# ESP32-S2 register map
Vendor: ESPRESSIF SYSTEMS (SHANGHAI) CO., LTD.; Series: ESP32 S-Series; File version: 20
CPU: Xtensa LX7 r0p0, little endian, no MPU, no FPU, 0 interrupt priority bits
Address unit: 32 bits
Registers are 32-bit, read-write, reset 0x0 unless marked. A register's access mark holds for its fields unless they carry their own. Offsets are from the block's base; [hi:lo] are bit positions; {n}, {i} and the like mark numbered series.

## SPI0 — SPI (Serial Peripheral Interface) Controller 0 (MEMSPI)
Base 0x3F403000
Same registers: SPI1 0x3F402000
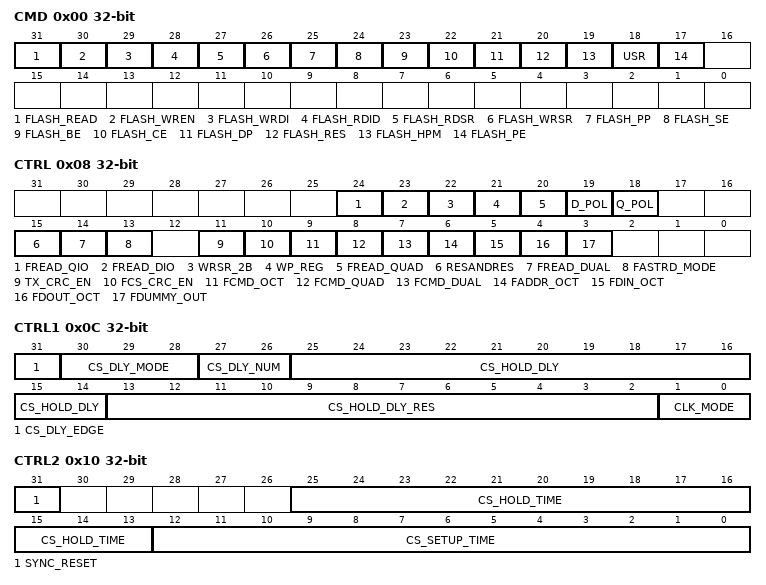
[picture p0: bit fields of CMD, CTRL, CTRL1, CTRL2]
0x00 CMD — SPI Memory Command Register
  [31] FLASH_READ, [30] FLASH_WREN, [29] FLASH_WRDI, [28] FLASH_RDID, [27] FLASH_RDSR, [26] FLASH_WRSR, [25] FLASH_PP, [24] FLASH_SE, [23] FLASH_BE, [22] FLASH_CE, [21] FLASH_DP, [20] FLASH_RES, [19] FLASH_HPM, [18] USR, [17] FLASH_PE
0x04 ADDR — SPI Memory Address Register
  [31:0] USR_ADDR_VALUE
0x08 CTRL — SPI Memory Control Register
  [24] FREAD_QIO, [23] FREAD_DIO, [22] WRSR_2B, [21] WP_REG, [20] FREAD_QUAD, [19] D_POL, [18] Q_POL, [15] RESANDRES, [14] FREAD_DUAL, [13] FASTRD_MODE, [11] TX_CRC_EN, [10] FCS_CRC_EN, [9] FCMD_OCT, [8] FCMD_QUAD, [7] FCMD_DUAL, [6] FADDR_OCT, [5] FDIN_OCT, [4] FDOUT_OCT, [3] FDUMMY_OUT
0x0C CTRL1 — SPI Memory Control1 Register
  [31] CS_DLY_EDGE, [30:28] CS_DLY_MODE, [27:26] CS_DLY_NUM, [25:14] CS_HOLD_DLY, [13:2] CS_HOLD_DLY_RES, [1:0] CLK_MODE
0x10 CTRL2 — SPI Memory Control2 Register
  [31] SYNC_RESET, [25:13] CS_HOLD_TIME, [12:0] CS_SETUP_TIME
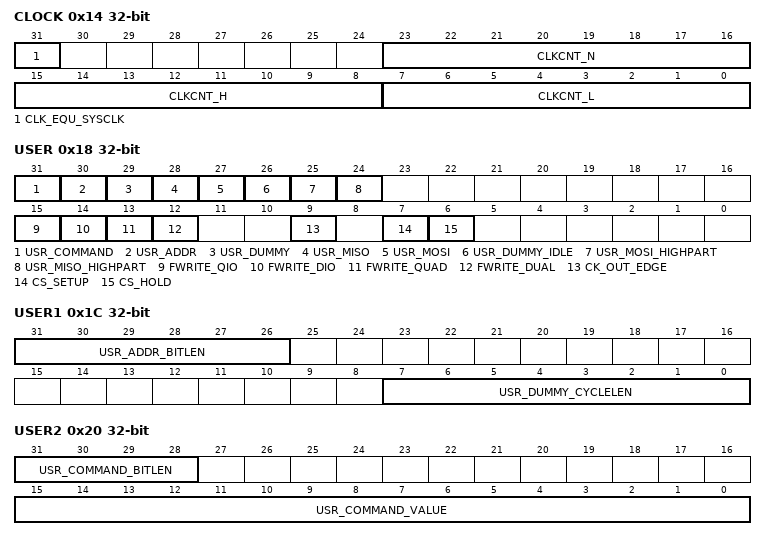
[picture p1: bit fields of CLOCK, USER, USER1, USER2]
0x14 CLOCK — SPI Memory Clock Register
  [31] CLK_EQU_SYSCLK, [23:16] CLKCNT_N, [15:8] CLKCNT_H, [7:0] CLKCNT_L
0x18 USER — SPI Memory User Register
  [31] USR_COMMAND, [30] USR_ADDR, [29] USR_DUMMY, [28] USR_MISO, [27] USR_MOSI, [26] USR_DUMMY_IDLE, [25] USR_MOSI_HIGHPART, [24] USR_MISO_HIGHPART, [15] FWRITE_QIO, [14] FWRITE_DIO, [13] FWRITE_QUAD, [12] FWRITE_DUAL, [9] CK_OUT_EDGE, [7] CS_SETUP, [6] CS_HOLD
0x1C USER1 — SPI Memory User1 Register
  [31:26] USR_ADDR_BITLEN, [7:0] USR_DUMMY_CYCLELEN
0x20 USER2 — SPI Memory User2 Register
  [31:28] USR_COMMAND_BITLEN, [15:0] USR_COMMAND_VALUE
0x24 MOSI_DLEN — SPI Memory MOSI Data Length Register
  [10:0] USR_MOSI_DBITLEN
0x28 MISO_DLEN — SPI Memory MISO Data Length Register
  [10:0] USR_MISO_DBITLEN
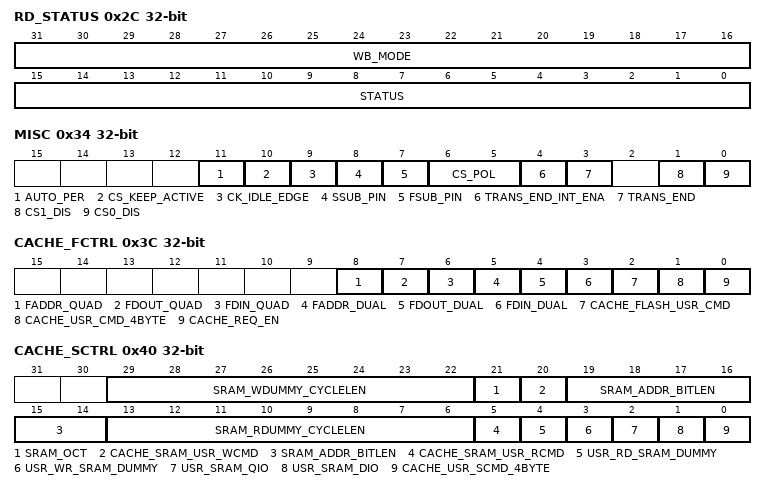
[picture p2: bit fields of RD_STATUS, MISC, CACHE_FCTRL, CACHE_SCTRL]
0x2C RD_STATUS — SPI Memory Read Status Register
  [31:16] WB_MODE, [15:0] STATUS
0x30 EXT_ADDR — SPI Memory External Address Register
0x34 MISC — SPI Memory Miscellaneous Register
  [11] AUTO_PER, [10] CS_KEEP_ACTIVE, [9] CK_IDLE_EDGE, [8] SSUB_PIN, [7] FSUB_PIN, [6:5] CS_POL, [4] TRANS_END_INT_ENA, [3] TRANS_END, [1] CS1_DIS, [0] CS0_DIS
0x38 TX_CRC — SPI Memory Transmit CRC Register
  [31:0] TX_CRC_DATA
0x3C CACHE_FCTRL — SPI Memory Cache Flash Control Register
  [8] FADDR_QUAD, [7] FDOUT_QUAD, [6] FDIN_QUAD, [5] FADDR_DUAL, [4] FDOUT_DUAL, [3] FDIN_DUAL, [2] CACHE_FLASH_USR_CMD, [1] CACHE_USR_CMD_4BYTE, [0] CACHE_REQ_EN
0x40 CACHE_SCTRL — SPI Memory Cache SCTRL Register
  [29:22] SRAM_WDUMMY_CYCLELEN, [21] SRAM_OCT, [20] CACHE_SRAM_USR_WCMD, [19:14] SRAM_ADDR_BITLEN, [13:6] SRAM_RDUMMY_CYCLELEN, [5] CACHE_SRAM_USR_RCMD, [4] USR_RD_SRAM_DUMMY, [3] USR_WR_SRAM_DUMMY, [2] USR_SRAM_QIO, [1] USR_SRAM_DIO, [0] CACHE_USR_SCMD_4BYTE
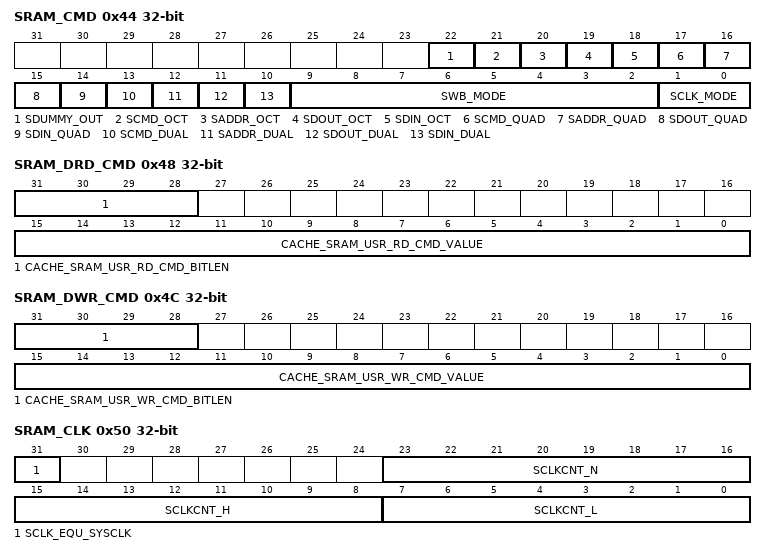
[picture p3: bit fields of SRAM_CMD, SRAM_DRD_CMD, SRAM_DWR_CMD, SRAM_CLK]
0x44 SRAM_CMD — SPI Memory SRAM Command Register
  [22] SDUMMY_OUT, [21] SCMD_OCT, [20] SADDR_OCT, [19] SDOUT_OCT, [18] SDIN_OCT, [17] SCMD_QUAD, [16] SADDR_QUAD, [15] SDOUT_QUAD, [14] SDIN_QUAD, [13] SCMD_DUAL, [12] SADDR_DUAL, [11] SDOUT_DUAL, [10] SDIN_DUAL, [9:2] SWB_MODE, [1:0] SCLK_MODE
0x48 SRAM_DRD_CMD — SPI Memory SRAM Read Command Register
  [31:28] CACHE_SRAM_USR_RD_CMD_BITLEN, [15:0] CACHE_SRAM_USR_RD_CMD_VALUE
0x4C SRAM_DWR_CMD — SPI Memory SRAM Write Command Register
  [31:28] CACHE_SRAM_USR_WR_CMD_BITLEN, [15:0] CACHE_SRAM_USR_WR_CMD_VALUE
0x50 SRAM_CLK — SPI Memory SRAM Clock Register
  [31] SCLK_EQU_SYSCLK, [23:16] SCLKCNT_N, [15:8] SCLKCNT_H, [7:0] SCLKCNT_L
0x54 FSM ro — SPI Memory FSM Register
  [2:0] ST
{0x58+4i} W{i} (i=0..15)
  [31:0] BUF
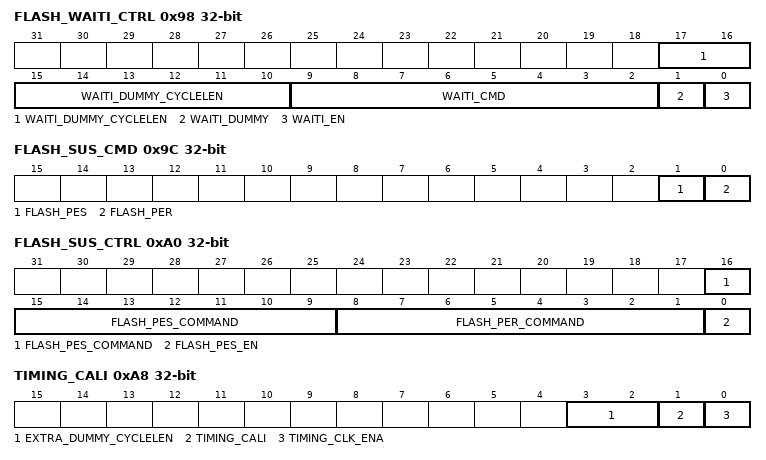
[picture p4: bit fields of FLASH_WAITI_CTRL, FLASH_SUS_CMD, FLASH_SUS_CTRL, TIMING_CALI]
0x98 FLASH_WAITI_CTRL — SPI Memory Flash Wait Idle Control Register
  [17:10] WAITI_DUMMY_CYCLELEN, [9:2] WAITI_CMD, [1] WAITI_DUMMY, [0] WAITI_EN
0x9C FLASH_SUS_CMD — SPI Memory Flash Suspend Command Register
  [1] FLASH_PES, [0] FLASH_PER
0xA0 FLASH_SUS_CTRL — SPI Memory Flash Suspend Control Register
  [16:9] FLASH_PES_COMMAND, [8:1] FLASH_PER_COMMAND, [0] FLASH_PES_EN
0xA4 SUS_STATUS ro — SPI Memory Suspend Status Register
  [0] FLASH_SUS
0xA8 TIMING_CALI — SPI Memory Timing Calibration Register
  [3:2] EXTRA_DUMMY_CYCLELEN, [1] TIMING_CALI, [0] TIMING_CLK_ENA
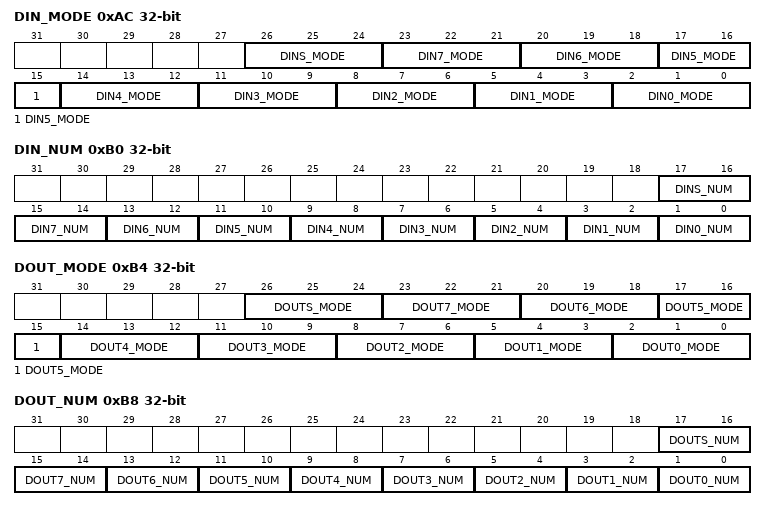
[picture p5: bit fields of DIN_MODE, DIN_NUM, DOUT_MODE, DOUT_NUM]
0xAC DIN_MODE — SPI Memory Data In Mode Register
  [26:24] DINS_MODE, [3n+2:3n] DIN{n}_MODE (n=0..7)
0xB0 DIN_NUM — SPI Memory Data In Number Register
  [17:16] DINS_NUM, [2n+1:2n] DIN{n}_NUM (n=0..7)
0xB4 DOUT_MODE — SPI Memory Data Out Mode Register
  [26:24] DOUTS_MODE, [3n+2:3n] DOUT{n}_MODE (n=0..7)
0xB8 DOUT_NUM — SPI Memory Data Out Number Register
  [17:16] DOUTS_NUM, [2n+1:2n] DOUT{n}_NUM (n=0..7)
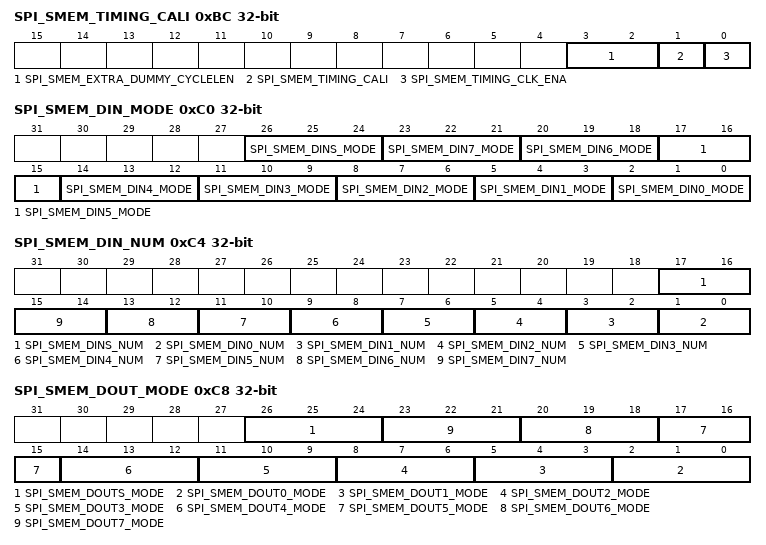
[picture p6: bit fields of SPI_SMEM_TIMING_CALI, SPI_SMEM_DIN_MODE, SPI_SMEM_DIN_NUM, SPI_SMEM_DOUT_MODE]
0xBC SPI_SMEM_TIMING_CALI — SPI Memory SRAM Timing Calibration Register
  [3:2] SPI_SMEM_EXTRA_DUMMY_CYCLELEN, [1] SPI_SMEM_TIMING_CALI, [0] SPI_SMEM_TIMING_CLK_ENA
0xC0 SPI_SMEM_DIN_MODE — SPI Memory SRAM Data In Mode Register
  [26:24] SPI_SMEM_DINS_MODE, [3n+2:3n] SPI_SMEM_DIN{n}_MODE (n=0..7)
0xC4 SPI_SMEM_DIN_NUM — SPI Memory SRAM Data In Number Register
  [17:16] SPI_SMEM_DINS_NUM, [2n+1:2n] SPI_SMEM_DIN{n}_NUM (n=0..7)
0xC8 SPI_SMEM_DOUT_MODE — SPI Memory SRAM Data Out Mode Register
  [26:24] SPI_SMEM_DOUTS_MODE, [3n+2:3n] SPI_SMEM_DOUT{n}_MODE (n=0..7)
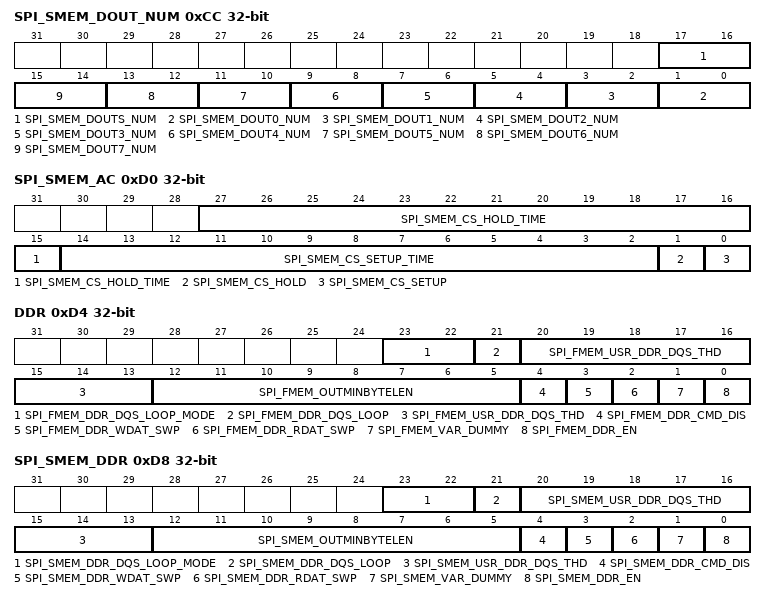
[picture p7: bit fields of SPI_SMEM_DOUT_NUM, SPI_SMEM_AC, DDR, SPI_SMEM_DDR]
0xCC SPI_SMEM_DOUT_NUM — SPI Memory SRAM Data Out Number Register
  [17:16] SPI_SMEM_DOUTS_NUM, [2n+1:2n] SPI_SMEM_DOUT{n}_NUM (n=0..7)
0xD0 SPI_SMEM_AC — SPI Memory SRAM Access Register
  [27:15] SPI_SMEM_CS_HOLD_TIME, [14:2] SPI_SMEM_CS_SETUP_TIME, [1] SPI_SMEM_CS_HOLD, [0] SPI_SMEM_CS_SETUP
0xD4 DDR — SPI Memory DDR Register
  [23:22] SPI_FMEM_DDR_DQS_LOOP_MODE, [21] SPI_FMEM_DDR_DQS_LOOP, [20:13] SPI_FMEM_USR_DDR_DQS_THD, [12:5] SPI_FMEM_OUTMINBYTELEN, [4] SPI_FMEM_DDR_CMD_DIS, [3] SPI_FMEM_DDR_WDAT_SWP, [2] SPI_FMEM_DDR_RDAT_SWP, [1] SPI_FMEM_VAR_DUMMY, [0] SPI_FMEM_DDR_EN
0xD8 SPI_SMEM_DDR — SPI Memory SRAM DDR Register
  [23:22] SPI_SMEM_DDR_DQS_LOOP_MODE, [21] SPI_SMEM_DDR_DQS_LOOP, [20:13] SPI_SMEM_USR_DDR_DQS_THD, [12:5] SPI_SMEM_OUTMINBYTELEN, [4] SPI_SMEM_DDR_CMD_DIS, [3] SPI_SMEM_DDR_WDAT_SWP, [2] SPI_SMEM_DDR_RDAT_SWP, [1] SPI_SMEM_VAR_DUMMY, [0] SPI_SMEM_DDR_EN
0xDC CLOCK_GATE — SPI Memory Clock Gate Register
  [0] CLK_EN
0x3FC DATE — SPI Memory Date Register
